AUTOSAR XML (schema 4-0-3)
package /ComponentTypes
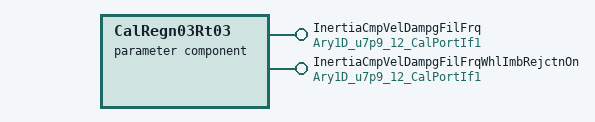
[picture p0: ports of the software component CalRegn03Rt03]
  parameter sw component type CalRegn03Rt03
    provide port InertiaCmpVelDampgFilFrq: parameter-provide-com-spec{init-value=12 x 8192, parameter=Ary1D}, provided-interface=Ary1D_u7p9_12_CalPortIf1
    provide port InertiaCmpVelDampgFilFrqWhlImbRejctnOn: parameter-provide-com-spec{init-value=12 x 8192, parameter=Ary1D}, provided-interface=Ary1D_u7p9_12_CalPortIf1
